AUTOSAR XML (schema 314)
package /ComponentType
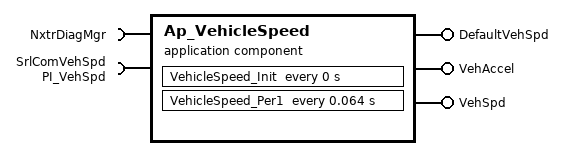
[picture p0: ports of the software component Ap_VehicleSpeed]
  application software component type Ap_VehicleSpeed
    provide port DefaultVehSpd: unqueued-sender-com-spec{data-element=Cnt_lgc, can-invalidate=false, init-value=D_BOOLEANFALSE_CNT_LGC}, provided-interface=DefaultVehSpd
    provide port VehAccel: unqueued-sender-com-spec{data-element=KphpS_f32, can-invalidate=false, init-value=D_FLOATZERO_ULS_F32}, provided-interface=VehAccel
    provide port VehSpd: unqueued-sender-com-spec{data-element=Kph_f32, can-invalidate=false, init-value=D_ZERO_ULS_F32}, provided-interface=VehSpd
    require port NxtrDiagMgr: required-com-specs=[GetNTCFailed, GetNTCStatus, ResetEventStatus, SetNTCStatus, SetOperationCycleState], required-interface=NxtrDiagMgr
    require port SrlComVehSpd: unqueued-receiver-com-spec{data-element=Kph_f32, init-value=D_FLOATZERO_ULS_F32}, required-interface=PI_VehSpd
  internal behavior Ap_VehicleSpeed_InternalBehavior: component=Ap_VehicleSpeed
    timing event VehicleSpeed_InitEvent: start-on-event=VehicleSpeed_Init, period=0
    timing event TMT_VehicleSpeed_Per1: start-on-event=VehicleSpeed_Per1, period=0.064
    inter runnable variable VehSpdFiltSV_Kph_u9p23: sw-calibration-access=READ-ONLY, type=UInt32, communication-approach=EXPLICIT, init-value=D_UNSIGNED32ZERO_CNT_U32
    port-api-options:
      enable-take-address=false, indirect-api=false, port=DefaultVehSpd
      enable-take-address=false, indirect-api=false, port=NxtrDiagMgr
      enable-take-address=false, indirect-api=false, port=SrlComVehSpd
      enable-take-address=false, indirect-api=false, port=VehAccel
      enable-take-address=false, indirect-api=false, port=VehSpd
    runnable VehicleSpeed_Init: written-variable=VehSpdFiltSV_Kph_u9p23
      data write access WRITE_VehSpd_Kph_f32: data-element=VehSpd.Kph_f32
    runnable VehicleSpeed_Per1: read-variable=VehSpdFiltSV_Kph_u9p23, written-variable=VehSpdFiltSV_Kph_u9p23
      data read access READ_SrlComVehSpd_Kph_f32: data-element=SrlComVehSpd.Kph_f32
      data write access WRITE_DefaultVehSpd_Cnt_lgc: data-element=DefaultVehSpd.Cnt_lgc
      data write access WRITE_VehAccel_KphpS_f32: data-element=VehAccel.KphpS_f32
      data write access WRITE_VehSpd_Kph_f32: data-element=VehSpd.Kph_f32
      sync call SC_NxtrDiagMgr_GetNTCFailed: operation=NxtrDiagMgr.GetNTCFailed, timeout=0
  swc implementation Ap_VehicleSpeed_Implementation: behavior=Ap_VehicleSpeed_InternalBehavior
    code-descriptors:
      code Code: type=SRC
